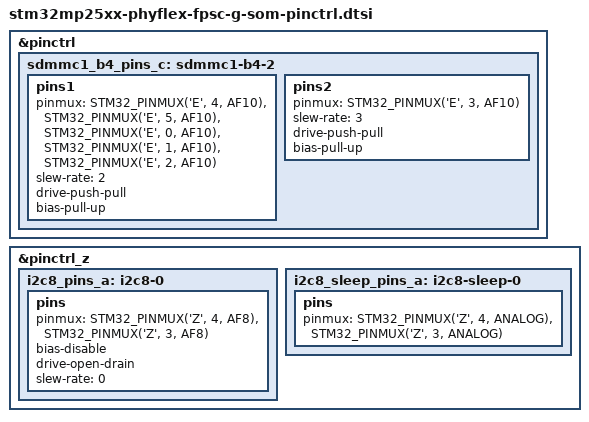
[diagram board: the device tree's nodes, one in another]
// SPDX-License-Identifier: (GPL-2.0+ OR BSD-3-Clause)
/*
 * Copyright (C) 2026 PHYTEC Messtechnik GmbH
 * Authors: Christophe Parant <c.parant@phytec.fr>
 *          Nicolas Raimundo <n.raimundo@phytec.fr>
 */
#include <dt-bindings/pinctrl/stm32-pinfunc.h>


&pinctrl {
	sdmmc1_b4_pins_c: sdmmc1-b4-2 {
		pins1 {
			pinmux = <STM32_PINMUX('E', 4, AF10)>, /* SDMMC1_D0 */
				 <STM32_PINMUX('E', 5, AF10)>, /* SDMMC1_D1 */
				 <STM32_PINMUX('E', 0, AF10)>, /* SDMMC1_D2 */
				 <STM32_PINMUX('E', 1, AF10)>, /* SDMMC1_D3 */
				 <STM32_PINMUX('E', 2, AF10)>; /* SDMMC1_CMD */
			slew-rate = <2>;
			drive-push-pull;
			bias-pull-up;
		};
		pins2 {
			pinmux = <STM32_PINMUX('E', 3, AF10)>; /* SDMMC1_CK */
			slew-rate = <3>;
			drive-push-pull;
			bias-pull-up;
		};
	};
};

&pinctrl_z {
	i2c8_pins_a: i2c8-0 {
		pins {
			pinmux = <STM32_PINMUX('Z', 4, AF8)>, /* I2C8_SCL */
				 <STM32_PINMUX('Z', 3, AF8)>; /* I2C8_SDA */
			bias-disable;
			drive-open-drain;
			slew-rate = <0>;
		};
	};

	i2c8_sleep_pins_a: i2c8-sleep-0 {
		pins {
			pinmux = <STM32_PINMUX('Z', 4, ANALOG)>, /* I2C8_SCL */
				 <STM32_PINMUX('Z', 3, ANALOG)>; /* I2C8_SDA */
		};
	};
};
